# MCU_FSS0_HPB_SS_CFG register map
Vendor: Texas Instruments
Peripheral module from a debugger description file (folder am65x).
Registers are 32-bit, read-only, reset values left out (the file's numbers can be read two ways) unless marked. A register's access mark holds for its fields unless they carry their own. Offsets are as the file gives them; lines under a group give offsets from that group; [hi:lo] are bit positions; {n}, {i} and the like mark numbered series; 'fields as' and 'values as' point back to an identical list; <NAME> marks a mode.

## MCU_FSS0_HPB_SS_CFG
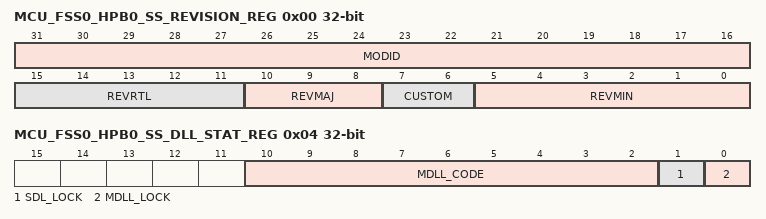
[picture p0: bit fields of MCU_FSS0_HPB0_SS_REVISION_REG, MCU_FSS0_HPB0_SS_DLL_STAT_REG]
0x00 MCU_FSS0_HPB0_SS_REVISION_REG — Revision Register The Revision Register contains the major and minor revisions for the module.
  [31:16] MODID — Module ID
  [15:11] REVRTL — RTL Revision
  [10:8] REVMAJ — Major Revision
  [7:6] CUSTOM
  [5:0] REVMIN — Minor Revision
0x04 MCU_FSS0_HPB0_SS_DLL_STAT_REG — DLL Status Register
  [10:2] MDLL_CODE — MDLL Code The slave delay line length that is currently enabled is determined by the MDLL Code value.
  [1] SDL_LOCK — MDLL Code Valid
  [0] MDLL_LOCK — MDLL Lock When this bit is set, it indicates that the master delay line in the MDLL is locked.
0x08 MCU_FSS0_HPB0_SS_RAM_STAT_REG — RAM Status Register This register is present on SR2.0 only.
  [0] INIT_DONE — FIFO RAM Initialization Done When this bit is set, it indicates that all the FIFO RAM auto initialization is complete. Software should check that this bit is set before initiating transactions to the external memory.
